# STM32H523 register map
File version: 1.2
CPU: CM33 r0p0, little endian, MPU, FPU, 4 interrupt priority bits
Registers are 32-bit, read-write, reset 0x0 unless marked. A register's access mark holds for its fields unless they carry their own. Offsets are from the block's base; [hi:lo] are bit positions; {n}, {i} and the like mark numbered series.

## GPIOA — GPIOA address block description
Base 0x42020000
Same registers: GPIOB 0x42020400, GPIOC 0x42020800, GPIOD 0x42020C00, GPIOE 0x42021000, GPIOF 0x42021400, GPIOG 0x42021800, GPIOH 0x42021C00, GPIOA_S 0x52020000, GPIOB_S 0x52020400, GPIOC_S 0x52020800, GPIOD_S 0x52020C00, GPIOE_S 0x52021000, GPIOF_S 0x52021400, GPIOG_S 0x52021800, GPIOH_S 0x52021C00
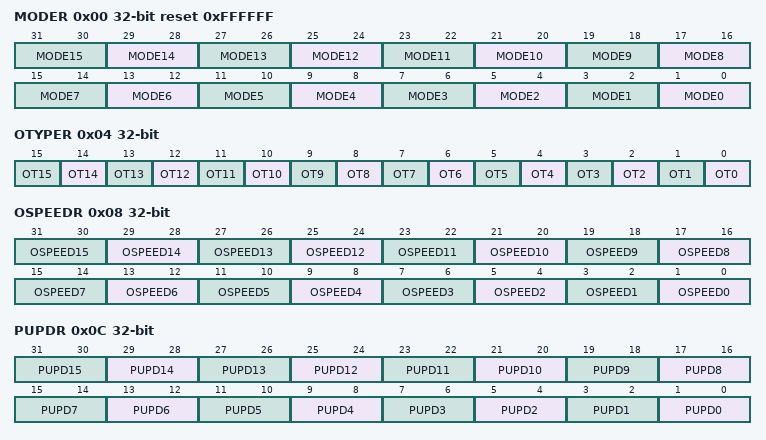
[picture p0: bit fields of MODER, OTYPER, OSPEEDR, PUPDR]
0x00 MODER reset 0xFFFFFF — GPIO port mode register
  [2n+1:2n] MODE{n} (n=0..15) — Port x configuration pin {n}
    0=Input mode; 1=Output (General purpose output mode); 2=Alternate function mode; 3=Analog mode
0x04 OTYPER — GPIO port output type register
  [n] OT{n} (n=0..15) — Port x configuration pin {n}
    0=PushPull (Output push-pull (reset state)); 1=OpenDrain (Output open-drain)
0x08 OSPEEDR — GPIO port output speed register
  [2n+1:2n] OSPEED{n} (n=0..15) — Port x configuration pin {n}
    0=LowSpeed; 1=MediumSpeed; 2=HighSpeed; 3=VeryHighSpeed
0x0C PUPDR — GPIO port pull-up/pull-down register
  [2n+1:2n] PUPD{n} (n=0..15) — Port x configuration pin {n}
    0=Floating (No pull-up, pull-down); 1=PullUp; 2=PullDown
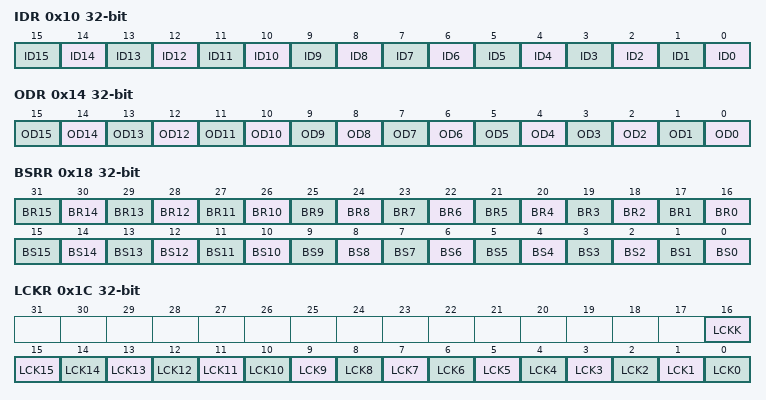
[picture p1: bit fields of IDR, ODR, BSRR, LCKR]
0x10 IDR ro (reset mask 0xFFFF0000) — GPIO port input data register
  [n] ID{n} (n=0..15) — Port input data pin {n}
    0=Low (Input is logic low); 1=High (Input is logic high)
0x14 ODR — GPIO port output data register
  [n] OD{n} (n=0..15) — Port output data pin {n}
    0=Low (Set output to logic low); 1=High (Set output to logic high)
0x18 BSRR wo — GPIO port bit set/reset register
  [n+16] BR{n} (n=0..15) — Port x reset pin {n}
    1=Resets the corresponding ODx bit
  [n] BS{n} (n=0..15) — Port x set pin {n}
    1=Set (Sets the corresponding ODx bit)
0x1C LCKR — GPIO port configuration lock register
  [16] LCKK — Lock key
    0=NotActive (Port configuration lock key not active); 1=Active (Port configuration lock key active)
  [n] LCK{n} (n=0..15) — Port x lock pin {n}
    0=Unlocked (Port configuration not locked); 1=Locked (Port configuration locked)
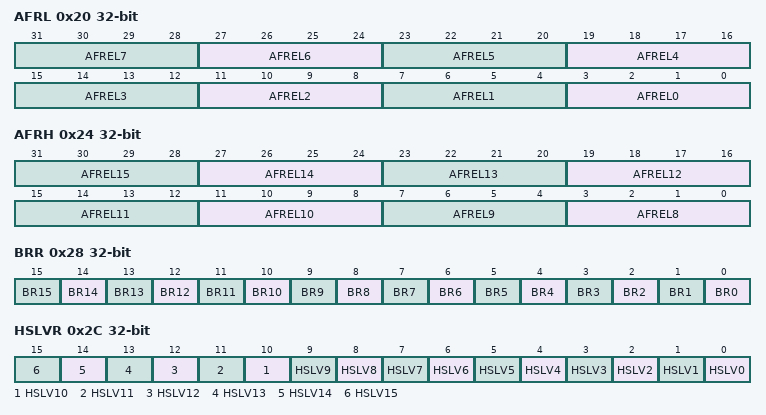
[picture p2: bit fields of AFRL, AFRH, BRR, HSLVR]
0x20 AFRL — GPIO alternate function low register
  [3:0] AFR{x} (x=EL0,EL1,EL2,EL3,EL4,EL5,EL6,EL7; step 4) — Alternate function selection for port x I/O pin y
    {v}=AF{v} (v=0..15)
0x24 AFRH — GPIO alternate function high register
  [3:0] AFR{x} (x=EL8,EL9,EL10,EL11,EL12,EL13,EL14,EL15; step 4) — Alternate function selection for port x I/O pin y
    {v}=AF{v} (v=0..15)
0x28 BRR wo — GPIO port bit reset register
  [n] BR{n} (n=0..15) — Port x reset pin {n}
    0=No action on the corresponding ODx bit; 1=Reset the ODx bit
0x2C HSLVR — GPIO high-speed low-voltage register
  [n] HSLV{n} (n=0..15) — Port x high-speed low-voltage configuration
    0=Disabled (I/O speed optimization disabled); 1=Enabled (I/O speed optimization enabled)
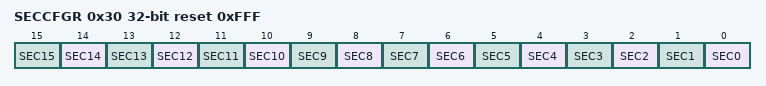
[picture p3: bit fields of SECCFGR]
0x30 SECCFGR reset 0xFFF — GPIO secure configuration register
  [n] SEC{n} (n=0..15) — I/O pin of Port x secure bit enable y
    0=NonSecure (The I/O pin is non-secure); 1=Secure (The I/O pin is secure)

## GPIOI — GPIOI address block description
Base 0x000001A0
Same registers: GPIOI_S 0x100001A0
Registers as GPIOA, without AFRH.

## HASH — HASH register bank
Base 0x420C0400
Same registers: HASH_S 0x520C0400
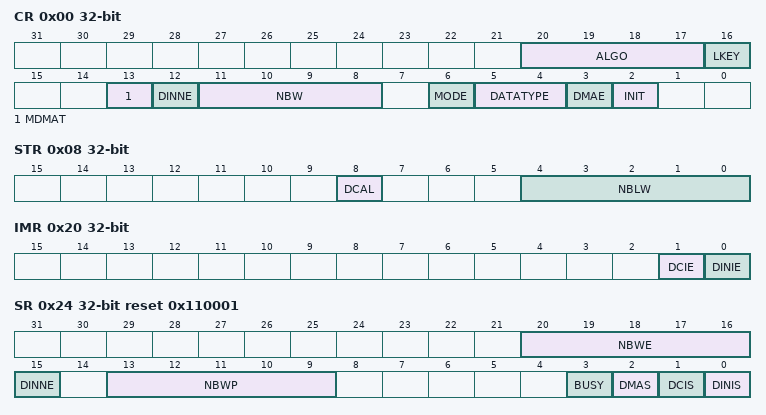
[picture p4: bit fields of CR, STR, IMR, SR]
0x00 CR — HASH control register
  [20:17] ALGO — Algorithm selection
  [16] LKEY — Long key selection
  [13] MDMAT — Multiple DMA transfers
  [12] DINNE ro — DIN not empty
  [11:8] NBW ro — Number of words already pushed
  [6] MODE — Mode selection
  [5:4] DATATYPE — Data type selection
  [3] DMAE — DMA enable
  [2] INIT — Initialize message digest calculation
0x04 DIN wo — HASH data input register
  [31:0] DATAIN — Data input
0x08 STR — HASH start register
  [8] DCAL — Digest calculation
  [4:0] NBLW — Number of valid bits in the last word
{0xC+4i} HRA{i} ro (i=0..4) — HASH aliased digest register {i}
  [31:0] H{i} — Hash data x
0x20 IMR — HASH interrupt enable register
  [1] DCIE — Digest calculation completion interrupt enable
  [0] DINIE — Data input interrupt enable
0x24 SR reset 0x110001 — HASH status register
  [20:16] NBWE ro — Number of words expected
  [15] DINNE ro — DIN not empty
  [13:9] NBWP ro — Number of words already pushed
  [3] BUSY ro — Busy bit
  [2] DMAS ro — DMA Status
  [1] DCIS — Digest calculation completion interrupt status
  [0] DINIS — Data input interrupt status
{0xF8+4i} CSR{i} (i=0..102) — HASH context swap register {i}
  [31:0] CS{i} — Context swap x
{0x310+4i} HR{i} ro (i=0..4) — HASH digest register {i}
  [31:0] H{i} — Hash data x
{0x310+4i} HR{i} ro (i=5..15) — HASH supplementary digest register {i}
  [31:0] H{i} — Hash data x
